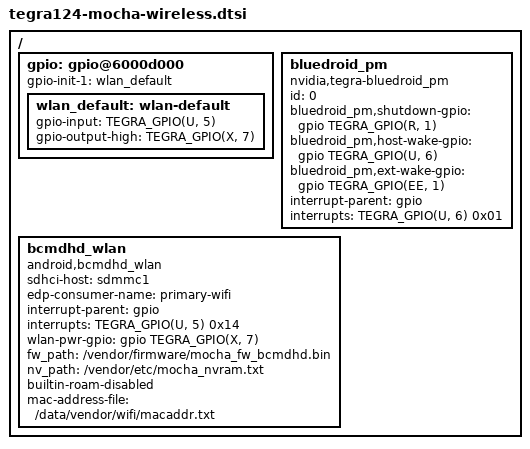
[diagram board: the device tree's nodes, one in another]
/*
 * arch/arm/boot/dts/tegra124-platforms/tegra124-mocha-wireless.dtsi
 *
 * Copyright (c) 2017, SmokeTeam. All rights reserved.
 *
 * This program is free software; you can redistribute it and/or modify it
 * under the terms and conditions of the GNU General Public License,
 * version 2, as published by the Free Software Foundation.
 *
 * This program is distributed in the hope it will be useful, but WITHOUT
 * ANY WARRANTY; without even the implied warranty of MERCHANTABILITY or
 * FITNESS FOR A PARTICULAR PURPOSE.  See the GNU General Public License for
 * more details.
 *
 */

/ {
	gpio: gpio@6000d000 {
		gpio-init-1 = <&wlan_default>;

		wlan_default: wlan-default {
			gpio-input = <
				TEGRA_GPIO(U, 5)
				>;
			gpio-output-high = <
				TEGRA_GPIO(X, 7)
				>;
		};
	};

	bluedroid_pm {
		compatible = "nvidia,tegra-bluedroid_pm";
		id = <0>;
		bluedroid_pm,shutdown-gpio = <&gpio TEGRA_GPIO(R, 1) 0>;
		bluedroid_pm,host-wake-gpio = <&gpio TEGRA_GPIO(U, 6) 0>;
		bluedroid_pm,ext-wake-gpio = <&gpio TEGRA_GPIO(EE, 1) 0>;
		interrupt-parent = <&gpio>;
		interrupts = <TEGRA_GPIO(U, 6) 0x01>;
	};
	
	bcmdhd_wlan {
		compatible = "android,bcmdhd_wlan";
		sdhci-host = <&sdmmc1>;
		edp-consumer-name = "primary-wifi";
		interrupt-parent = <&gpio>;
		interrupts = <TEGRA_GPIO(U, 5) 0x14>;
		wlan-pwr-gpio = <&gpio TEGRA_GPIO(X, 7) 0>;
		status = "okay";
		fw_path = "/vendor/firmware/mocha_fw_bcmdhd.bin";
		nv_path = "/vendor/etc/mocha_nvram.txt";
		/*
		 * The firmware's own roaming stays off, as it was when the driver
		 * was built with DISABLE_BUILTIN_ROAM; the driver taken from 4.9
		 * builds roaming in and asks the tree whether to turn it off.
		 */
		builtin-roam-disabled;
		/*
		 * conn_init writes the address here, and it has to be a path it
		 * can write: /vendor is mounted read-only, so the old location
		 * under /vendor/etc never held a file at all and this property
		 * did nothing.
		 *
		 * The file matters more than it looks. nv_path above carries a
		 * Broadcom sample address, and the module parameter that would
		 * override it is consumed once and cleared by the driver:
		 *
		 *     firmware_path[0] = '\0';
		 *     nvram_path[0] = '\0';
		 *
		 * so only the first firmware download after boot sees the real
		 * address. Android 10 reloads the firmware before every connect
		 * attempt -- ClientModeImpl asks for the factory MAC, and on this
		 * driver setting a MAC means ifdown/ifup -- and each of those
		 * reloads fell back to the sample. This path is read on every
		 * download instead, so the address survives them.
		 */
		mac-address-file = "/data/vendor/wifi/macaddr.txt";

		/*
		 * No country_code_map. NVIDIA's table turned ISO codes into the
		 * locales of their firmware's CLM (US -> Q2/998, EU -> E0/994);
		 * 7.81.3 turns them down ("set country for US as Q2 rev 998
		 * failed"), which left the firmware on the nvram's country and a
		 * 5 GHz hotspot refused by the framework.
		 * Without a table the driver sends the ISO code with rev -1, the
		 * firmware's own default for that country; brcmfmac, which runs
		 * this firmware on the Chromebooks it comes from, sends plain ISO
		 * codes too.
		 */
	};
};
